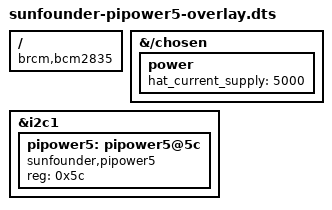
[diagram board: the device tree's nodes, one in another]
/dts-v1/;
/plugin/;

/ {
	compatible = "brcm,bcm2835";

	fragment@0 {
		target-path = "/chosen";
		__overlay__ {
			power: power {
				hat_current_supply = <5000>;
			};
		};
	};
	fragment@1 {
		target = <&i2c1>;
		__overlay__ {
			#address-cells = <1>;
			#size-cells = <0>;
			status = "okay";

			pipower5: pipower5@5c {
				compatible = "sunfounder,pipower5";
				reg = <0x5c>;
				status = "okay";
			};
		};
	};

};
